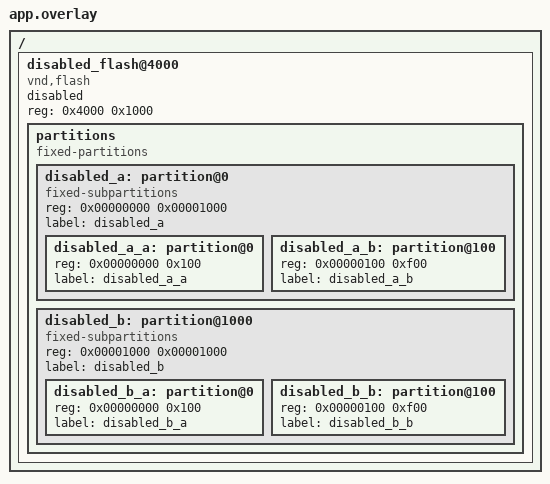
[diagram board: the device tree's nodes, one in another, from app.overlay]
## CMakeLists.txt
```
# SPDX-License-Identifier: Apache-2.0

cmake_minimum_required(VERSION 3.28.0)
find_package(Zephyr REQUIRED HINTS $ENV{ZEPHYR_BASE})
project(flash_map)

if(NOT CONFIG_FLASH_AREA_CHECK_INTEGRITY)
  FILE(GLOB app_sources src/main.c)
else()
  FILE(GLOB app_sources src/main_sha.c)
endif()

target_sources(app PRIVATE ${app_sources})
```

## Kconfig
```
#
# Copyright (c) 2025 Nordic Semiconductor ASA
#
# SPDX-License-Identifier: Apache-2.0
#

mainmenu "Flash Map test configuration"

config TEST_FLASH_MAP_DISABLED_PARTITIONS
	bool "Test support for disabled partitions"
	default y if !FLASH_MAP_CUSTOM
	help
	  Test flash_area_open for returning -ENOENT for disabled partitions.
	  Note that custom flash maps may not support disabled partitions
	  and therefore not even generated id for them. In such case it would
	  not be possible to provide disabled partition id to flash_area_open,
	  making this test impossible to run.

config TEST_FLASH_MAP_NODE_MACROS
	bool "Test DTS macros for accessing partition info via DTS node"
	default y if !FLASH_MAP_CUSTOM
	help
	  Custom flash map may be defined outside of DTS definition, therefore
	  not have a DTS nodes for partitions.

menu "Zephyr"
source "Kconfig.zephyr"
endmenu
```

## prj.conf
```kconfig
CONFIG_ZTEST=y
CONFIG_ZTEST_STACK_SIZE=2048
CONFIG_FLASH=y
CONFIG_FLASH_PAGE_LAYOUT=y
CONFIG_FLASH_MAP=y
```

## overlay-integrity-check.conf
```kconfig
CONFIG_FLASH_AREA_CHECK_INTEGRITY=y
CONFIG_TEST_RANDOM_GENERATOR=y
```

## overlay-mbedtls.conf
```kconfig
CONFIG_FLASH_AREA_CHECK_INTEGRITY=y
CONFIG_FLASH_AREA_CHECK_INTEGRITY_MBEDTLS=y
```

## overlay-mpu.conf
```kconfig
CONFIG_MPU_ALLOW_FLASH_WRITE=y
CONFIG_SYS_TIMEOUT_LEGACY_API=n
```

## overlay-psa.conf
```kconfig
CONFIG_FLASH_AREA_CHECK_INTEGRITY=y
CONFIG_FLASH_AREA_CHECK_INTEGRITY_PSA=y
CONFIG_MBEDTLS=y
CONFIG_MBEDTLS_PSA_CRYPTO_C=y
CONFIG_TEST_RANDOM_GENERATOR=y
```

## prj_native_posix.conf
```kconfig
CONFIG_ZTEST=y
CONFIG_FLASH=y
CONFIG_FLASH_PAGE_LAYOUT=y
CONFIG_FLASH_MAP=y
CONFIG_FLASH_AREA_CHECK_INTEGRITY=y
```

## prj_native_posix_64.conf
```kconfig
CONFIG_ZTEST=y
CONFIG_FLASH=y
CONFIG_FLASH_PAGE_LAYOUT=y
CONFIG_FLASH_MAP=y
```

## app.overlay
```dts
/*
 * Copyright (c) 2022, Commonwealth Scientific and Industrial Research
 * Organisation (CSIRO) ABN 41 687 119 230.
 *
 * SPDX-License-Identifier: Apache-2.0
 *
 * Test compilation with subpartitions and disabled flash nodes.
 */

/ {
	disabled_flash@4000 {
		compatible = "vnd,flash";
		reg = <0x4000 0x1000>;
		ranges = <0x0 0x4000 0x1000>;
		#address-cells = <1>;
		#size-cells = <1>;
		status = "disabled";

		partitions {
			compatible = "fixed-partitions";
			ranges;
			#address-cells = <1>;
			#size-cells = <1>;

			disabled_a: partition@0 {
				compatible = "fixed-subpartitions";
				reg = <0x00000000 0x00001000>;
				ranges = <0x0 0x0 0x1000>;
				label = "disabled_a";
				#address-cells = <1>;
				#size-cells = <1>;

				disabled_a_a: partition@0 {
					reg = <0x00000000 0x100>;
					label = "disabled_a_a";
				};

				disabled_a_b: partition@100 {
					reg = <0x00000100 0xf00>;
					label = "disabled_a_b";
				};
			};

			disabled_b: partition@1000 {
				compatible = "fixed-subpartitions";
				reg = <0x00001000 0x00001000>;
				ranges = <0x0 0x1000 0x1000>;
				label = "disabled_b";
				#address-cells = <1>;
				#size-cells = <1>;

				disabled_b_a: partition@0 {
					reg = <0x00000000 0x100>;
					label = "disabled_b_a";
				};

				disabled_b_b: partition@100 {
					reg = <0x00000100 0xf00>;
					label = "disabled_b_b";
				};
			};
		};
	};
};
```

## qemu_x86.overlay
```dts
/*
 * Copyright (c) 2020 Intel Corporation
 *
 * SPDX-License-Identifier: Apache-2.0
 */

#include <mem.h>

/delete-node/ &storage_partition;

&flash_sim0 {
	/*
	 * Sync with qemu_x86.dts on partitions to make sure
	 * size is large enough and there are no overlaps.
	 */

	partitions {
		scratch_partition: partition@31000 {
			label = "image_scratch";

			reg = <0x31000 DT_SIZE_K(32)>;
		};
		storage_partition: partition@39000 {
			label = "storage";

			reg = <0x39000 DT_SIZE_K(32)>;
		};
	};
};
```

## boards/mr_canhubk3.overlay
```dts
/*
 * Copyright 2023 NXP
 *
 * SPDX-License-Identifier: Apache-2.0
 */

#include "../app.overlay"

/*
 * Currently there's no support for mcuboot, so create a partition for this test.
 */
&mx25l6433f {
	partitions {
		slot1_partition: partition@100000 {
			reg = <0x100000 0x100000>;
		};
	};
};
```

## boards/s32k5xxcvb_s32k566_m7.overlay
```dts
/*
 * Copyright 2025 NXP
 *
 * SPDX-License-Identifier: Apache-2.0
 */

#include "../app.overlay"

&is66wvh8m8dall {
	partitions {
		slot1_partition: partition@100000 {
			reg = <0x100000 0x100000>;
		};
	};
};
```

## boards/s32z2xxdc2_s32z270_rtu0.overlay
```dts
/*
 * Copyright 2024 NXP
 *
 * SPDX-License-Identifier: Apache-2.0
 */

#include "../app.overlay"

&s26hs512t {
	partitions {
		slot1_partition: partition@100000 {
			reg = <0x100000 0x100000>;
		};
	};
};
```

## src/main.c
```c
/*
 * Copyright (c) 2017 Nordic Semiconductor ASA
 * Copyright (c) 2015 Runtime Inc
 * Copyright (c) 2020 Gerson Fernando Budke <nandojve@gmail.com>
 * Copyright 2024 NXP
 *
 * SPDX-License-Identifier: Apache-2.0
 */

#include <zephyr/ztest.h>
#include <zephyr/drivers/flash.h>
#include <zephyr/storage/flash_map.h>

#define SLOT1_PARTITION		slot1_partition
#define SLOT1_PARTITION_ID	PARTITION_ID(SLOT1_PARTITION)
#define SLOT1_PARTITION_DEV	PARTITION_DEVICE(SLOT1_PARTITION)
#define SLOT1_PARTITION_NODE	DT_NODELABEL(SLOT1_PARTITION)
#define SLOT1_PARTITION_OFFSET	PARTITION_OFFSET(SLOT1_PARTITION)
#define SLOT1_PARTITION_SIZE	PARTITION_SIZE(SLOT1_PARTITION)

#define FLASH_AREA_COPY_SIZE	MIN((SLOT1_PARTITION_SIZE / 2), 128)

extern int flash_map_entries;
struct flash_sector fs_sectors[2048];

ZTEST(flash_map, test_flash_area_disabled_device)
{
	/* The test checks if Flash Map will report partition
	 * non-existend if it is disabled, but it also assumes that
	 * disabled partition will have an ID generated.
	 * Custom partition maps may not be generating entries for
	 * disabled partitions nor identifiers, which makes the
	 * test fail with custom partition manager, for no real reason.
	 */
#if defined(CONFIG_TEST_FLASH_MAP_DISABLED_PARTITIONS)
	const struct flash_area *fa;
	int rc;

	/* Test that attempting to open a disabled flash area fails */
	rc = flash_area_open(PARTITION_ID(disabled_a), &fa);
	zassert_equal(rc, -ENOENT, "Open did not fail");
	rc = flash_area_open(PARTITION_ID(disabled_a_a), &fa);
	zassert_equal(rc, -ENOENT, "Open did not fail");
	rc = flash_area_open(PARTITION_ID(disabled_a_b), &fa);
	zassert_equal(rc, -ENOENT, "Open did not fail");
	rc = flash_area_open(PARTITION_ID(disabled_b), &fa);
	zassert_equal(rc, -ENOENT, "Open did not fail");
	rc = flash_area_open(PARTITION_ID(disabled_b_a), &fa);
	zassert_equal(rc, -ENOENT, "Open did not fail");
	rc = flash_area_open(PARTITION_ID(disabled_b_b), &fa);
	zassert_equal(rc, -ENOENT, "Open did not fail");

	/* Note lack of tests for PARTITION(...) instantiation,
	 * because this macro will fail, at compile time, if node does not
	 * exist or is disabled.
	 */
#else
	ztest_test_skip();
#endif
}

ZTEST(flash_map, test_flash_area_device_is_ready)
{
	const struct flash_area no_dev = {
		.fa_dev = NULL,
	};

	zassert_false(flash_area_device_is_ready(NULL));
	zassert_false(flash_area_device_is_ready(&no_dev));
	/* The below just assumes that tests are executed so late that
	 * all devices are already initialized and ready.
	 */
	zassert_true(flash_area_device_is_ready(
			PARTITION(SLOT1_PARTITION)));
}

static void layout_match(const struct device *flash_dev, uint32_t sec_cnt)
{
	off_t off = 0;
	int i;

	/* For each reported sector, check if it corresponds to real page on device */
	for (i = 0; i < sec_cnt; ++i) {
		struct flash_pages_info fpi;

		zassert_ok(
			flash_get_page_info_by_offs(flash_dev, SLOT1_PARTITION_OFFSET + off, &fpi));
		/* Offset of page taken directly from device corresponds to offset
		 * within flash area
		 */
		zassert_equal(fpi.start_offset, fs_sectors[i].fs_off + SLOT1_PARTITION_OFFSET);
		zassert_equal(fpi.size, fs_sectors[i].fs_size);
		off += fs_sectors[i].fs_size;
	}
}

/**
 * @brief Test flash_area_get_sectors()
 */
ZTEST(flash_map, test_flash_area_get_sectors)
{
	const struct flash_area *fa;
	const struct device *flash_dev_a = SLOT1_PARTITION_DEV;
	uint32_t sec_cnt;
	int rc;

	fa = PARTITION(SLOT1_PARTITION);

	zassert_true(flash_area_device_is_ready(fa));

	zassert_true(device_is_ready(flash_dev_a));

	/* Device obtained by label should match the one from fa object */
	zassert_equal(fa->fa_dev, flash_dev_a, "Device for slot1_partition do not match");

	memset(&fs_sectors[0], 0, sizeof(fs_sectors));

	sec_cnt = ARRAY_SIZE(fs_sectors);
	rc = flash_area_get_sectors(SLOT1_PARTITION_ID, &sec_cnt, fs_sectors);
	zassert_true(rc == 0, "flash_area_get_sectors failed");

	layout_match(flash_dev_a, sec_cnt);
}

ZTEST(flash_map, test_flash_area_sectors)
{
	const struct flash_area *fa;
	uint32_t sec_cnt;
	int rc;
	const struct device *flash_dev_a = SLOT1_PARTITION_DEV;

	fa = PARTITION(SLOT1_PARTITION);

	zassert_true(flash_area_device_is_ready(fa));

	zassert_true(device_is_ready(flash_dev_a));

	/* Device obtained by label should match the one from fa object */
	zassert_equal(fa->fa_dev, flash_dev_a, "Device for slot1_partition do not match");

	sec_cnt = ARRAY_SIZE(fs_sectors);
	rc = flash_area_sectors(fa, &sec_cnt, fs_sectors);
	zassert_true(rc == 0, "flash_area_get_sectors failed");

	layout_match(flash_dev_a, sec_cnt);
}

ZTEST(flash_map, test_flash_area_erased_val)
{
	const struct flash_parameters *param;
	const struct flash_area *fa;
	uint8_t val;

	fa = PARTITION(SLOT1_PARTITION);

	val = flash_area_erased_val(fa);

	param = flash_get_parameters(fa->fa_dev);

	zassert_equal(param->erase_value, val,
		      "value different than the flash erase value");
}

ZTEST(flash_map, test_fixed_partition_node_macros)
{
	/* DTS node macros, for accessing fixed partitions, are only available
	 * for DTS based partitions; custom flash map may define partition outside
	 * of DTS definition, making the NODE macros fail to evaluate.
	 */
#if defined(CONFIG_TEST_FLASH_MAP_NODE_MACROS)
	/* Test against changes in API */
#if DT_NODE_HAS_COMPAT(SLOT1_PARTITION_NODE, zephyr_mapped_partition)
	zassert_equal(PARTITION_NODE_ADDRESS(SLOT1_PARTITION_NODE),
		DT_REG_ADDR(SLOT1_PARTITION_NODE));
#else
	zassert_equal(PARTITION_NODE_OFFSET(SLOT1_PARTITION_NODE),
		DT_REG_ADDR(SLOT1_PARTITION_NODE));
#endif
	zassert_equal(PARTITION_NODE_SIZE(SLOT1_PARTITION_NODE),
		DT_REG_SIZE(SLOT1_PARTITION_NODE));
	zassert_equal(PARTITION_NODE_DEVICE(SLOT1_PARTITION_NODE),
		DEVICE_DT_GET(DT_MTD_FROM_PARTITION(SLOT1_PARTITION_NODE)));

	/* Taking by node and taking by label should give same device */
	zassert_equal(PARTITION_BY_NODE(DT_NODELABEL(SLOT1_PARTITION)),
		      PARTITION(SLOT1_PARTITION));
#else
	ztest_test_skip();
#endif
}

ZTEST(flash_map, test_fixed_subpartition_node_macros)
{
	/* DTS node macros, for accessing fixed partitions, are only available
	 * for DTS based partitions; custom flash map may define partition outside
	 * of DTS definition, making the NODE macros fail to evaluate.
	 */
#if defined(CONFIG_TEST_FLASH_MAP_NODE_MACROS)
	/* Test that both partitions and subpartitions exist */
	zassert_true(PARTITION_EXISTS(disabled_a));
	zassert_true(PARTITION_EXISTS(disabled_a_a));
	zassert_true(PARTITION_EXISTS(disabled_a_b));

	/* Test that the subpartition offset is relative to the parent */
	zassert_equal(PARTITION_OFFSET(disabled_b),
		      PARTITION_OFFSET(disabled_b_a));
	zassert_equal(PARTITION_OFFSET(disabled_b) + 0x100,
		      PARTITION_OFFSET(disabled_b_b));
	zassert_equal(PARTITION_NODE_OFFSET(DT_NODELABEL(disabled_b)),
		      PARTITION_NODE_OFFSET(DT_NODELABEL(disabled_b_a)));
	zassert_equal(
		PARTITION_NODE_OFFSET(DT_NODELABEL(disabled_b)) + 0x100,
		PARTITION_NODE_OFFSET(DT_NODELABEL(disabled_b_b)));

	/* Test that the subpartition address is relative to the parent */
	zassert_equal(PARTITION_ADDRESS(disabled_b),
		      PARTITION_ADDRESS(disabled_b_a));
	zassert_equal(PARTITION_ADDRESS(disabled_b) + 0x100,
		      PARTITION_ADDRESS(disabled_b_b));
	zassert_equal(PARTITION_NODE_ADDRESS(DT_NODELABEL(disabled_b)),
		      PARTITION_NODE_ADDRESS(DT_NODELABEL(disabled_b_a)));
	zassert_equal(
		PARTITION_NODE_ADDRESS(DT_NODELABEL(disabled_b)) + 0x100,
		PARTITION_NODE_ADDRESS(DT_NODELABEL(disabled_b_b)));
#else
	ztest_test_skip();
#endif
}

ZTEST(flash_map, test_flash_area_erase_and_flatten)
{
	int i;
	bool erased = true;
	int rc;
	const struct flash_area *fa;
	const struct device *flash_dev;

	fa = PARTITION(SLOT1_PARTITION);

	/* First erase the area so it's ready for use. */
	flash_dev = flash_area_get_device(fa);

	rc = flash_erase(flash_dev, fa->fa_off, fa->fa_size);
	zassert_true(rc == 0, "flash area erase fail");

	rc = flash_fill(flash_dev, 0xaa, fa->fa_off, fa->fa_size);
	zassert_true(rc == 0, "flash device fill fail");

	rc = flash_area_erase(fa, 0, fa->fa_size);
	zassert_true(rc == 0, "flash area erase fail");

	TC_PRINT("Flash area info:\n");
	TC_PRINT("\tpointer:\t %p\n", &fa);
	TC_PRINT("\toffset:\t %ld\n", (long)fa->fa_off);
	TC_PRINT("\tsize:\t %ld\n", (long)fa->fa_size);

	/* we work under assumption that flash_fill is working and tested */
	i = 0;
	while (erased && i < fa->fa_size) {
		uint8_t buf[32];
		int chunk = MIN(sizeof(buf), fa->fa_size - i);

		rc = flash_read(flash_dev, fa->fa_off + i, buf, chunk);
		zassert_equal(rc, 0, "Unexpected read fail with error %d", rc);
		for (int ii = 0; ii < chunk; ++ii, ++i) {
			if ((uint8_t)buf[ii] != (uint8_t)flash_area_erased_val(fa)) {
				erased = false;
				break;
			}
		}
	}
	zassert_true(erased, "Erase failed at dev abosolute offset index %d",
		     (int)(i + fa->fa_off));

	rc = flash_fill(flash_dev, 0xaa, fa->fa_off, fa->fa_size);
	zassert_true(rc == 0, "flash device fill fail");

	rc = flash_area_flatten(fa, 0, fa->fa_size);

	erased = true;
	i = 0;
	while (erased && i < fa->fa_size) {
		uint8_t buf[32];
		int chunk = MIN(sizeof(buf), fa->fa_size - i);

		rc = flash_read(flash_dev, fa->fa_off + i, buf, chunk);
		zassert_equal(rc, 0, "Unexpected read fail with error %d", rc);
		for (int ii = 0; ii < chunk; ++ii, ++i) {
			if ((uint8_t)buf[ii] != (uint8_t)flash_area_erased_val(fa)) {
				erased = false;
				break;
			}
		}
	}
	zassert_true(erased, "Flatten/Erase failed at dev absolute offset %d",
		     (int)(i + fa->fa_off));
}

ZTEST(flash_map, test_flash_area_copy)
{
	const struct flash_area *fa;
	uint8_t src_buf[FLASH_AREA_COPY_SIZE], dst_buf[FLASH_AREA_COPY_SIZE],
		copy_buf[32];
	int rc;

	/* Get source and destination flash areas */
	fa = PARTITION(SLOT1_PARTITION);

	/* First erase the area so it's ready for use. */
	rc = flash_area_erase(fa, 0, fa->fa_size);
	zassert_true(rc == 0, "flash area erase fail");

	/* Fill source area with test data */
	memset(src_buf, 0xAB, sizeof(src_buf));
	rc = flash_area_write(fa, 0, src_buf, sizeof(src_buf));
	zassert_true(rc == 0, "Failed to write to source flash area");

	/* Perform the copy operation */
	rc = flash_area_copy(fa, 0, fa, FLASH_AREA_COPY_SIZE, sizeof(src_buf), copy_buf,
			     sizeof(copy_buf));
	zassert_true(rc == 0, "flash_area_copy failed");

	/* Verify the copied data */
	rc = flash_area_read(fa, FLASH_AREA_COPY_SIZE, dst_buf, sizeof(dst_buf));
	zassert_true(rc == 0, "Failed to read from destination flash area");
	zassert_mem_equal(src_buf, dst_buf, sizeof(src_buf), "Data mismatch after copy");
}

ZTEST(flash_map, test_parameter_overflows)
{
	const struct flash_area *fa;
	uint8_t dst_buf[FLASH_AREA_COPY_SIZE];
	int rc;

	fa = PARTITION(SLOT1_PARTITION);
	/* -1 cast to size_t gives us max size_t value, added to offset of 1,
	 * it will overflow to 0.
	 */
	rc = flash_area_read(fa, 1, dst_buf, (size_t)(-1));
	zassert_equal(rc, -EINVAL, "1: Overflow should have been detected");
	/* Here we have offset 1 below size of area, with added max size_t
	 * it upper bound of read range should overflow to:
	 * (max(size_t) + fa->fa_size - 1) mod (max(size_t)) == fa->fa_size - 2
	 */
	rc = flash_area_read(fa, fa->fa_size - 1, dst_buf, (size_t)(-1));
	zassert_equal(rc, -EINVAL, "2: Overflow should have been detected");
}

ZTEST_SUITE(flash_map, NULL, NULL, NULL, NULL, NULL);
```

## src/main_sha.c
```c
/*
 * Copyright (c) 2017-2024 Nordic Semiconductor ASA
 * Copyright (c) 2015 Runtime Inc
 * Copyright (c) 2020 Gerson Fernando Budke <nandojve@gmail.com>
 * Copyright 2024 NXP
 *
 * SPDX-License-Identifier: Apache-2.0
 */

#include <zephyr/ztest.h>
#include <zephyr/drivers/flash.h>
#include <zephyr/storage/flash_map.h>

#define SLOT1_PARTITION		slot1_partition
#define SLOT1_PARTITION_ID	PARTITION_ID(SLOT1_PARTITION)
#define SLOT1_PARTITION_DEV	PARTITION_DEVICE(SLOT1_PARTITION)
#define SLOT1_PARTITION_NODE	DT_NODELABEL(SLOT1_PARTITION)
#define SLOT1_PARTITION_OFFSET	PARTITION_OFFSET(SLOT1_PARTITION)

ZTEST(flash_map_sha, test_flash_area_check_int_sha256)
{
	/* for i in {1..16}; do echo $'0123456789abcdef\nfedcba98765432' >> tst.sha; done
	 * hexdump tst.sha
	 */
	uint8_t tst_vec[] = { 0x30, 0x31, 0x32, 0x33, 0x34, 0x35, 0x36, 0x37,
			      0x38, 0x39, 0x61, 0x62, 0x63, 0x64, 0x65, 0x66,
			      0x0a, 0x66, 0x65, 0x64, 0x63, 0x62, 0x61, 0x39,
			      0x38, 0x37, 0x36, 0x35, 0x34, 0x33, 0x32, 0x0a,
			      0x30, 0x31, 0x32, 0x33, 0x34, 0x35, 0x36, 0x37,
			      0x38, 0x39, 0x61, 0x62, 0x63, 0x64, 0x65, 0x66,
			      0x0a, 0x66, 0x65, 0x64, 0x63, 0x62, 0x61, 0x39,
			      0x38, 0x37, 0x36, 0x35, 0x34, 0x33, 0x32, 0x0a,
			      0x30, 0x31, 0x32, 0x33, 0x34, 0x35, 0x36, 0x37,
			      0x38, 0x39, 0x61, 0x62, 0x63, 0x64, 0x65, 0x66,
			      0x0a, 0x66, 0x65, 0x64, 0x63, 0x62, 0x61, 0x39,
			      0x38, 0x37, 0x36, 0x35, 0x34, 0x33, 0x32, 0x0a,
			      0x30, 0x31, 0x32, 0x33, 0x34, 0x35, 0x36, 0x37,
			      0x38, 0x39, 0x61, 0x62, 0x63, 0x64, 0x65, 0x66,
			      0x0a, 0x66, 0x65, 0x64, 0x63, 0x62, 0x61, 0x39,
			      0x38, 0x37, 0x36, 0x35, 0x34, 0x33, 0x32, 0x0a,
			      0x30, 0x31, 0x32, 0x33, 0x34, 0x35, 0x36, 0x37,
			      0x38, 0x39, 0x61, 0x62, 0x63, 0x64, 0x65, 0x66,
			      0x0a, 0x66, 0x65, 0x64, 0x63, 0x62, 0x61, 0x39,
			      0x38, 0x37, 0x36, 0x35, 0x34, 0x33, 0x32, 0x0a,
			      0x30, 0x31, 0x32, 0x33, 0x34, 0x35, 0x36, 0x37,
			      0x38, 0x39, 0x61, 0x62, 0x63, 0x64, 0x65, 0x66,
			      0x0a, 0x66, 0x65, 0x64, 0x63, 0x62, 0x61, 0x39,
			      0x38, 0x37, 0x36, 0x35, 0x34, 0x33, 0x32, 0x0a,
			      0x30, 0x31, 0x32, 0x33, 0x34, 0x35, 0x36, 0x37,
			      0x38, 0x39, 0x61, 0x62, 0x63, 0x64, 0x65, 0x66,
			      0x0a, 0x66, 0x65, 0x64, 0x63, 0x62, 0x61, 0x39,
			      0x38, 0x37, 0x36, 0x35, 0x34, 0x33, 0x32, 0x0a,
			      0x30, 0x31, 0x32, 0x33, 0x34, 0x35, 0x36, 0x37,
			      0x38, 0x39, 0x61, 0x62, 0x63, 0x64, 0x65, 0x66,
			      0x0a, 0x66, 0x65, 0x64, 0x63, 0x62, 0x61, 0x39,
			      0x38, 0x37, 0x36, 0x35, 0x34, 0x33, 0x32, 0x0a,
			      0x30, 0x31, 0x32, 0x33, 0x34, 0x35, 0x36, 0x37,
			      0x38, 0x39, 0x61, 0x62, 0x63, 0x64, 0x65, 0x66,
			      0x0a, 0x66, 0x65, 0x64, 0x63, 0x62, 0x61, 0x39,
			      0x38, 0x37, 0x36, 0x35, 0x34, 0x33, 0x32, 0x0a,
			      0x30, 0x31, 0x32, 0x33, 0x34, 0x35, 0x36, 0x37,
			      0x38, 0x39, 0x61, 0x62, 0x63, 0x64, 0x65, 0x66,
			      0x0a, 0x66, 0x65, 0x64, 0x63, 0x62, 0x61, 0x39,
			      0x38, 0x37, 0x36, 0x35, 0x34, 0x33, 0x32, 0x0a,
			      0x30, 0x31, 0x32, 0x33, 0x34, 0x35, 0x36, 0x37,
			      0x38, 0x39, 0x61, 0x62, 0x63, 0x64, 0x65, 0x66,
			      0x0a, 0x66, 0x65, 0x64, 0x63, 0x62, 0x61, 0x39,
			      0x38, 0x37, 0x36, 0x35, 0x34, 0x33, 0x32, 0x0a,
			      0x30, 0x31, 0x32, 0x33, 0x34, 0x35, 0x36, 0x37,
			      0x38, 0x39, 0x61, 0x62, 0x63, 0x64, 0x65, 0x66,
			      0x0a, 0x66, 0x65, 0x64, 0x63, 0x62, 0x61, 0x39,
			      0x38, 0x37, 0x36, 0x35, 0x34, 0x33, 0x32, 0x0a,
			      0x30, 0x31, 0x32, 0x33, 0x34, 0x35, 0x36, 0x37,
			      0x38, 0x39, 0x61, 0x62, 0x63, 0x64, 0x65, 0x66,
			      0x0a, 0x66, 0x65, 0x64, 0x63, 0x62, 0x61, 0x39,
			      0x38, 0x37, 0x36, 0x35, 0x34, 0x33, 0x32, 0x0a,
			      0x30, 0x31, 0x32, 0x33, 0x34, 0x35, 0x36, 0x37,
			      0x38, 0x39, 0x61, 0x62, 0x63, 0x64, 0x65, 0x66,
			      0x0a, 0x66, 0x65, 0x64, 0x63, 0x62, 0x61, 0x39,
			      0x38, 0x37, 0x36, 0x35, 0x34, 0x33, 0x32, 0x0a,
			      0x30, 0x31, 0x32, 0x33, 0x34, 0x35, 0x36, 0x37,
			      0x38, 0x39, 0x61, 0x62, 0x63, 0x64, 0x65, 0x66,
			      0x0a, 0x66, 0x65, 0x64, 0x63, 0x62, 0x61, 0x39,
			      0x38, 0x37, 0x36, 0x35, 0x34, 0x33, 0x32, 0x0a,
			      0x30, 0x31, 0x32, 0x33, 0x34, 0x35, 0x36, 0x37,
			      0x38, 0x39, 0x61, 0x62, 0x63, 0x64, 0x65, 0x66,
			      0x0a, 0x66, 0x65, 0x64, 0x63, 0x62, 0x61, 0x39,
			      0x38, 0x37, 0x36, 0x35, 0x34, 0x33, 0x32, 0x0a };
	/* sha256sum tst.sha */
	uint8_t tst_sha[] = { 0xae, 0xed, 0x7d, 0x59, 0x53, 0xbd, 0xb7, 0x28,
			      0x3e, 0x59, 0xc2, 0x65, 0x59, 0x62, 0xe3, 0x7e,
			      0xfa, 0x97, 0xbd, 0x76, 0xf6, 0xac, 0xc3, 0x92,
			      0x59, 0x48, 0x4e, 0xc0, 0xaf, 0xa8, 0x49, 0x65 };

	const struct flash_area *fa;
	struct flash_area_check fac = { NULL, 0, -1, NULL, 0 };
	uint8_t buffer[16];
	int rc;

	rc = flash_area_open(SLOT1_PARTITION_ID, &fa);
	zassert_true(rc == 0, "flash_area_open() fail, error %d\n", rc);
	rc = flash_area_erase(fa, 0, fa->fa_size);
	zassert_true(rc == 0, "Flash erase failure, error %d\n", rc);
	rc = flash_area_write(fa, 0, tst_vec, sizeof(tst_vec));
	zassert_true(rc == 0, "Flash img write, error %d\n", rc);

	rc = flash_area_check_int_sha256(NULL, NULL);
	zassert_true(rc == -EINVAL, "Flash area check int 256 params 1, 2\n");
	rc = flash_area_check_int_sha256(NULL, &fac);
	zassert_true(rc == -EINVAL, "Flash area check int 256 params 2\n");
	rc = flash_area_check_int_sha256(fa, NULL);
	zassert_true(rc == -EINVAL, "Flash area check int 256 params 1\n");

	rc = flash_area_check_int_sha256(fa, &fac);
	zassert_true(rc == -EINVAL, "Flash area check int 256 fac match\n");
	fac.match = tst_sha;
	rc = flash_area_check_int_sha256(fa, &fac);
	zassert_true(rc == -EINVAL, "Flash area check int 256 fac clen\n");
	fac.clen = sizeof(tst_vec);
	rc = flash_area_check_int_sha256(fa, &fac);
	zassert_true(rc == -EINVAL, "Flash area check int 256 fac off\n");
	fac.off = 0;
	rc = flash_area_check_int_sha256(fa, &fac);
	zassert_true(rc == -EINVAL, "Flash area check int 256 fac rbuf\n");
	fac.rbuf = buffer;
	rc = flash_area_check_int_sha256(fa, &fac);
	zassert_true(rc == -EINVAL, "Flash area check int 256 fac rblen\n");
	fac.rblen = sizeof(buffer);

	rc = flash_area_check_int_sha256(fa, &fac);
	zassert_true(rc == 0, "Flash area check int 256 OK, error %d\n", rc);
	tst_sha[0] = 0x00;
	rc = flash_area_check_int_sha256(fa, &fac);
	zassert_false(rc == 0, "Flash area check int 256 wrong sha\n");

	flash_area_close(fa);
}

ZTEST_SUITE(flash_map_sha, NULL, NULL, NULL, NULL, NULL);
```
